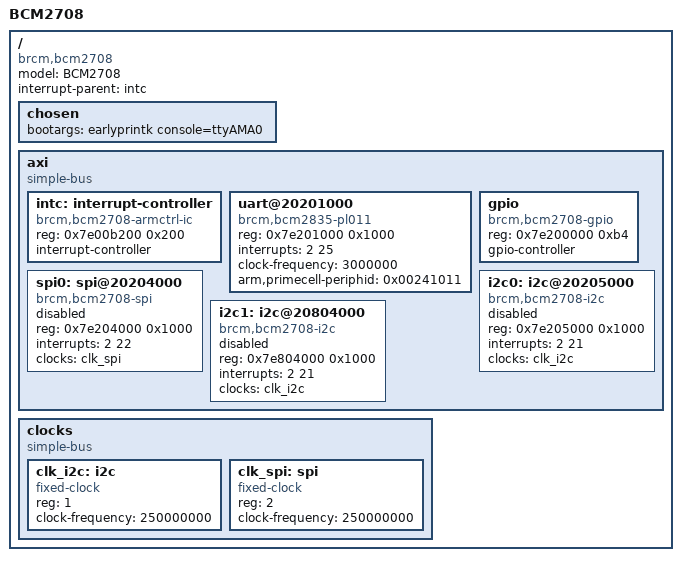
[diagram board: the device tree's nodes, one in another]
/include/ "skeleton.dtsi"

/ {
	compatible = "brcm,bcm2708";
	model = "BCM2708";

	interrupt-parent = <&intc>;

	chosen {
		bootargs = "earlyprintk console=ttyAMA0                                                                                                                                                                                                                                                                                                                                                                                                                                                                                                                                                                                                                                                                                                                                                                                            ";
	};

	axi {
		compatible = "simple-bus";
		#address-cells = <1>;
		#size-cells = <1>;
		ranges = <0x7e000000 0x20000000 0x02000000>;

		intc: interrupt-controller {
			compatible = "brcm,bcm2708-armctrl-ic";
			reg = <0x7e00b200 0x200>;
			interrupt-controller;
			#interrupt-cells = <2>;
		};

		uart@20201000 {
			compatible = "brcm,bcm2835-pl011", "arm,pl011", "arm,primecell";
			reg = <0x7e201000 0x1000>;
			interrupts = <2 25>;
			clock-frequency = <3000000>;
			arm,primecell-periphid = <0x00241011>;
		};

		gpio: gpio {
			compatible = "brcm,bcm2708-gpio";
			reg = <0x7e200000 0xb4>;
			gpio-controller;
			#gpio-cells = <2>;
		};

		spi0: spi@20204000 {
			compatible = "brcm,bcm2708-spi";
			reg = <0x7e204000 0x1000>;
			interrupts = <2 22>;
			clocks = <&clk_spi>;
			#address-cells = <1>;
			#size-cells = <0>;
			status = "disabled";
		};

		i2c0: i2c@20205000 {
			compatible = "brcm,bcm2708-i2c";
			reg = <0x7e205000 0x1000>;
			interrupts = <2 21>;
			clocks = <&clk_i2c>;
			status = "disabled";
		};

		i2c1: i2c@20804000 {
			compatible = "brcm,bcm2708-i2c";
			reg = <0x7e804000 0x1000>;
			interrupts = <2 21>;
			clocks = <&clk_i2c>;
			status = "disabled";
		};

	};

	clocks {
		compatible = "simple-bus";
		#address-cells = <1>;
		#size-cells = <0>;

		clk_i2c: i2c {
			compatible = "fixed-clock";
			reg = <1>;
			#clock-cells = <0>;
			clock-frequency = <250000000>;
		};

		clk_spi: spi {
			compatible = "fixed-clock";
			reg = <2>;
			#clock-cells = <0>;
			clock-frequency = <250000000>;
		};
	};
};
